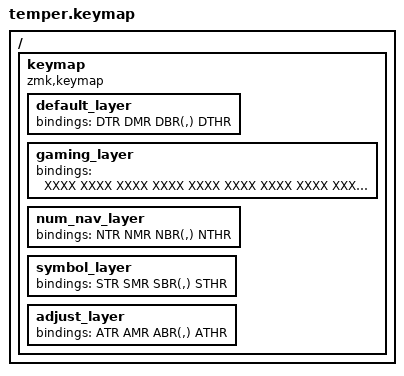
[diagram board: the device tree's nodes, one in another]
#include <behaviors.dtsi>

#include "base.keymap"

/ {
  keymap {
    compatible = "zmk,keymap";
    default_layer { 
      bindings = <
        DTR
        DMR
        DBR(,)
        DTHR
      >;
    };

    gaming_layer { 
      bindings = <
        XXXX XXXX XXXX XXXX XXXX  XXXX XXXX XXXX XXXX XXXX
        XXXX XXXX XXXX XXXX XXXX  XXXX XXXX XXXX XXXX XXXX
        XXXX XXXX XXXX XXXX XXXX  XXXX XXXX XXXX XXXX XXXX
                  XXXX XXXX XXXX  XXXX XXXX XXXX
      >;
    };
        
    num_nav_layer { 
      bindings = <
        NTR
        NMR
        NBR(,)
        NTHR
      >;
    };

    symbol_layer { 
      bindings = <
        STR
        SMR
        SBR(,)
        STHR
      >;
    };
        
    adjust_layer { 
      bindings = <
        ATR
        AMR
        ABR(,)
        ATHR
      >;
    };
  };
};
